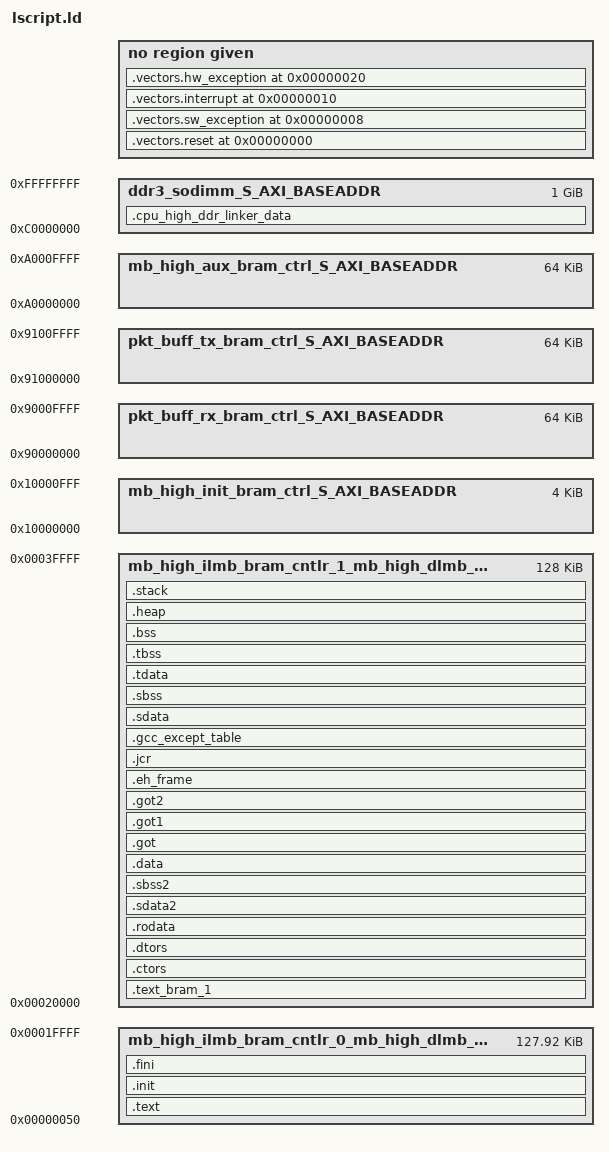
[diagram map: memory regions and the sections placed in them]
/*******************************************************************/
/*                                                                 */
/* This file is automatically generated by linker script generator.*/
/*                                                                 */
/* Version: Xilinx EDK 14.4 EDK_P.49d                              */
/*                                                                 */
/* Copyright (c) 2010 Xilinx, Inc.  All rights reserved.           */
/*                                                                 */
/* Description : MicroBlaze Linker Script                          */
/*                                                                 */
/*******************************************************************/

_STACK_SIZE = DEFINED(_STACK_SIZE) ? _STACK_SIZE : 0x1000;
_HEAP_SIZE  = DEFINED(_HEAP_SIZE)  ? _HEAP_SIZE  : 0x2000;


/* Define Memories in the system */

MEMORY
{
   mb_high_ilmb_bram_cntlr_0_mb_high_dlmb_bram_cntlr_0 : ORIGIN = 0x00000050, LENGTH = 0x0001FFB0
   mb_high_ilmb_bram_cntlr_1_mb_high_dlmb_bram_cntlr_1 : ORIGIN = 0x00020000, LENGTH = 0x00020000
   mb_high_init_bram_ctrl_S_AXI_BASEADDR               : ORIGIN = 0x10000000, LENGTH = 0x00001000
   pkt_buff_rx_bram_ctrl_S_AXI_BASEADDR                : ORIGIN = 0x90000000, LENGTH = 0x00010000
   pkt_buff_tx_bram_ctrl_S_AXI_BASEADDR                : ORIGIN = 0x91000000, LENGTH = 0x00010000
   mb_high_aux_bram_ctrl_S_AXI_BASEADDR                : ORIGIN = 0xA0000000, LENGTH = 0x00010000
   ddr3_sodimm_S_AXI_BASEADDR                          : ORIGIN = 0xC0000000, LENGTH = 0x40000000
}

/* Specify the default entry point to the program */

ENTRY(_start)

/* Define the sections, and where they are mapped in memory */

SECTIONS
{
.vectors.reset 0x00000000 : {
   KEEP (*(.vectors.reset))
} 

.vectors.sw_exception 0x00000008 : {
   KEEP (*(.vectors.sw_exception))
} 

.vectors.interrupt 0x00000010 : {
   KEEP (*(.vectors.interrupt))
} 

.vectors.hw_exception 0x00000020 : {
   KEEP (*(.vectors.hw_exception))
} 

/******************************************************************
 * CPU High Code Sections
 *
 * In order to make building the FPGA XPS project easier, the CPU High
 * LMB memory was divided into two distict memories:
 *     - mb_high_ilmb_bram_cntlr_0_mb_high_dlmb_bram_cntlr_0
 *     - mb_high_ilmb_bram_cntlr_1_mb_high_dlmb_bram_cntlr_1
 *
 * However, this means that to use both memories, we need to specify
 * which sections use each memory.  This can pose a challenge with the
 * large code sections.  Therefore, the linker command file defines
 * a .text_bram_1 which lives in mb_high_dlmb_bram_cntlr_1 and a 
 * .text section which lives in mb_high_dlmb_bram_cntlr_0.
 *
 * The .text_bram_1 section can be modified to include other code by 
 * adding other directives, without modifying any other files.  Some
 * additional includes could be:
 *    *src*(.text)
 *    *wlan_mac_common*(.text)
 *
 * NOTE:  Order matters in the linker file.  The .text_bram_1 section 
 *     come before the .text section which contains *(.text) and  
 *     *(.text.*), which will catch the remaining code. 
 *
 ******************************************************************/
.text_bram_1 : {
   *wlan_mac_high_framework*(.text)
} > mb_high_ilmb_bram_cntlr_1_mb_high_dlmb_bram_cntlr_1

.text : {
   *(.text)
   *(.text.*)
   *wlan_mac_common*(.text)
   *(.gnu.linkonce.t.*)
} > mb_high_ilmb_bram_cntlr_0_mb_high_dlmb_bram_cntlr_0

/******************************************************************
 * CPU High Linker Data in DDR
 *
 * Since on device BRAM is being used for many different things, it 
 * becomes necessary to link data sections into DDR.  The section
 * cpu_high_ddr_linker_data is used for this data.
 *
 * However, since this section is located in DDR, which cannot be 
 * loaded by the SDK, we inlucde the (NOLOAD) directive for this 
 * section.  This means that the initial value of the section will be 
 * random (ie whatever was last in DDR).  
 *
 * If this section needs to be initialized, then the function
 * wlan_mac_high_cpu_linker_data_init() must be updated in 
 * wlan_mac_high.c.
 *
 ******************************************************************/
.cpu_high_ddr_linker_data (NOLOAD) : {
   __cpu_high_ddr_linker_data_start = .;
   *(.eth_data)
   __cpu_high_ddr_linker_data_end = .;
} > ddr3_sodimm_S_AXI_BASEADDR

.init : {
   KEEP (*(.init))
} > mb_high_ilmb_bram_cntlr_0_mb_high_dlmb_bram_cntlr_0

.fini : {
   KEEP (*(.fini))
} > mb_high_ilmb_bram_cntlr_0_mb_high_dlmb_bram_cntlr_0

.ctors : {
   __CTOR_LIST__ = .;
   ___CTORS_LIST___ = .;
   KEEP (*crtbegin.o(.ctors))
   KEEP (*(EXCLUDE_FILE(*crtend.o) .ctors))
   KEEP (*(SORT(.ctors.*)))
   KEEP (*(.ctors))
   __CTOR_END__ = .;
   ___CTORS_END___ = .;
} > mb_high_ilmb_bram_cntlr_1_mb_high_dlmb_bram_cntlr_1

.dtors : {
   __DTOR_LIST__ = .;
   ___DTORS_LIST___ = .;
   KEEP (*crtbegin.o(.dtors))
   KEEP (*(EXCLUDE_FILE(*crtend.o) .dtors))
   KEEP (*(SORT(.dtors.*)))
   KEEP (*(.dtors))
   PROVIDE(__DTOR_END__ = .);
   PROVIDE(___DTORS_END___ = .);
} > mb_high_ilmb_bram_cntlr_1_mb_high_dlmb_bram_cntlr_1

.rodata : {
   __rodata_start = .;
   *(.rodata)
   *(.rodata.*)
   *(.gnu.linkonce.r.*)
   __rodata_end = .;
} > mb_high_ilmb_bram_cntlr_1_mb_high_dlmb_bram_cntlr_1

.sdata2 : {
   . = ALIGN(8);
   __sdata2_start = .;
   *(.sdata2)
   *(.sdata2.*)
   *(.gnu.linkonce.s2.*)
   . = ALIGN(8);
   __sdata2_end = .;
} > mb_high_ilmb_bram_cntlr_1_mb_high_dlmb_bram_cntlr_1

.sbss2 : {
   __sbss2_start = .;
   *(.sbss2)
   *(.sbss2.*)
   *(.gnu.linkonce.sb2.*)
   __sbss2_end = .;
} > mb_high_ilmb_bram_cntlr_1_mb_high_dlmb_bram_cntlr_1

.data : {
   . = ALIGN(4);
   __data_start = .;
   *(.data)
   *(.data.*)
   *(.gnu.linkonce.d.*)
   __data_end = .;
} > mb_high_ilmb_bram_cntlr_1_mb_high_dlmb_bram_cntlr_1

.got : {
   *(.got)
} > mb_high_ilmb_bram_cntlr_1_mb_high_dlmb_bram_cntlr_1

.got1 : {
   *(.got1)
} > mb_high_ilmb_bram_cntlr_1_mb_high_dlmb_bram_cntlr_1

.got2 : {
   *(.got2)
} > mb_high_ilmb_bram_cntlr_1_mb_high_dlmb_bram_cntlr_1

.eh_frame : {
   *(.eh_frame)
} > mb_high_ilmb_bram_cntlr_1_mb_high_dlmb_bram_cntlr_1

.jcr : {
   *(.jcr)
} > mb_high_ilmb_bram_cntlr_1_mb_high_dlmb_bram_cntlr_1

.gcc_except_table : {
   *(.gcc_except_table)
} > mb_high_ilmb_bram_cntlr_1_mb_high_dlmb_bram_cntlr_1

.sdata : {
   . = ALIGN(8);
   __sdata_start = .;
   *(.sdata)
   *(.sdata.*)
   *(.gnu.linkonce.s.*)
   . += 16;                  /* fix for linker false error message */
   __sdata_end = .;
} > mb_high_ilmb_bram_cntlr_1_mb_high_dlmb_bram_cntlr_1

.sbss (NOLOAD) : {
   . = ALIGN(4);
   __sbss_start = .;
   *(.sbss)
   *(.sbss.*)
   *(.gnu.linkonce.sb.*)
   . = ALIGN(8);
   __sbss_end = .;
} > mb_high_ilmb_bram_cntlr_1_mb_high_dlmb_bram_cntlr_1

.tdata : {
   __tdata_start = .;
   *(.tdata)
   *(.tdata.*)
   *(.gnu.linkonce.td.*)
   __tdata_end = .;
} > mb_high_ilmb_bram_cntlr_1_mb_high_dlmb_bram_cntlr_1

.tbss : {
   __tbss_start = .;
   *(.tbss)
   *(.tbss.*)
   *(.gnu.linkonce.tb.*)
   __tbss_end = .;
} > mb_high_ilmb_bram_cntlr_1_mb_high_dlmb_bram_cntlr_1

.bss (NOLOAD) : {
   . = ALIGN(4);
   __bss_start = .;
   *(.bss)
   *(.bss.*)
   *(.gnu.linkonce.b.*)
   *(COMMON)
   . = ALIGN(4);
   __bss_end = .;
} > mb_high_ilmb_bram_cntlr_1_mb_high_dlmb_bram_cntlr_1

_SDA_BASE_  = __sdata_start  + ((__sbss_end  - __sdata_start)  / 2 );

_SDA2_BASE_ = __sdata2_start + ((__sbss2_end - __sdata2_start) / 2 );

/* Generate Stack and Heap definitions */

.heap (NOLOAD) : {
   . = ALIGN(8);
   _heap = .;
   _heap_start = .;
   . += _HEAP_SIZE;
   _heap_end = .;
} > mb_high_ilmb_bram_cntlr_1_mb_high_dlmb_bram_cntlr_1

.stack (NOLOAD) : {
   _stack_end = .;
   . += _STACK_SIZE;
   . = ALIGN(8);
   _stack = .;
   __stack = _stack;
} > mb_high_ilmb_bram_cntlr_1_mb_high_dlmb_bram_cntlr_1

_end = .;
}

